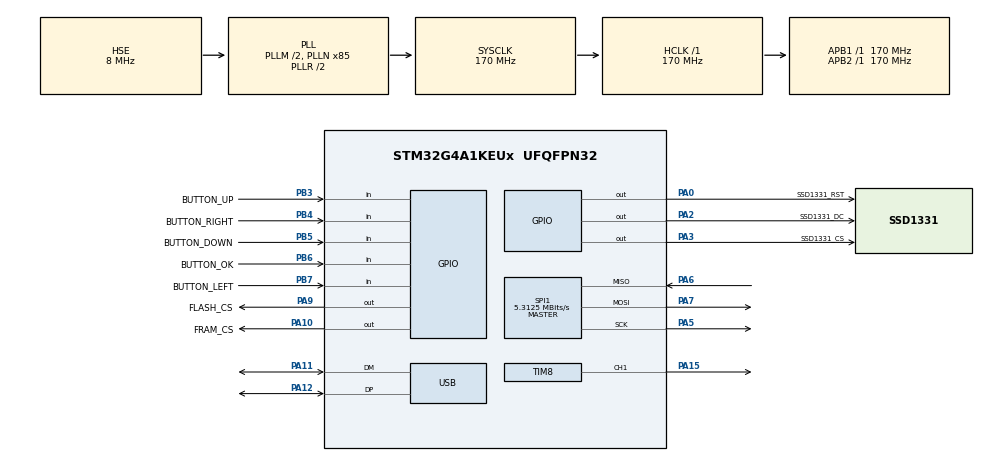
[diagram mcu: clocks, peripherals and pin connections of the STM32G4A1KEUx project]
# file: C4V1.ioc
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Dma.CORDIC_READ.0.Direction=DMA_PERIPH_TO_MEMORY
Dma.CORDIC_READ.0.EventEnable=DISABLE
Dma.CORDIC_READ.0.Instance=DMA1_Channel2
Dma.CORDIC_READ.0.MemDataAlignment=DMA_MDATAALIGN_WORD
Dma.CORDIC_READ.0.MemInc=DMA_MINC_ENABLE
Dma.CORDIC_READ.0.Mode=DMA_NORMAL
Dma.CORDIC_READ.0.PeriphDataAlignment=DMA_PDATAALIGN_WORD
Dma.CORDIC_READ.0.PeriphInc=DMA_PINC_DISABLE
Dma.CORDIC_READ.0.Polarity=HAL_DMAMUX_REQ_GEN_RISING
Dma.CORDIC_READ.0.Priority=DMA_PRIORITY_LOW
Dma.CORDIC_READ.0.RequestNumber=1
Dma.CORDIC_READ.0.SignalID=NONE
Dma.CORDIC_READ.0.SyncEnable=DISABLE
Dma.CORDIC_READ.0.SyncPolarity=HAL_DMAMUX_SYNC_NO_EVENT
Dma.CORDIC_READ.0.SyncRequestNumber=1
Dma.CORDIC_READ.0.SyncSignalID=NONE
Dma.CORDIC_WRITE.1.Direction=DMA_MEMORY_TO_PERIPH
Dma.CORDIC_WRITE.1.EventEnable=DISABLE
Dma.CORDIC_WRITE.1.Instance=DMA1_Channel3
Dma.CORDIC_WRITE.1.MemDataAlignment=DMA_MDATAALIGN_WORD
Dma.CORDIC_WRITE.1.MemInc=DMA_MINC_ENABLE
Dma.CORDIC_WRITE.1.Mode=DMA_NORMAL
Dma.CORDIC_WRITE.1.PeriphDataAlignment=DMA_PDATAALIGN_WORD
Dma.CORDIC_WRITE.1.PeriphInc=DMA_PINC_DISABLE
Dma.CORDIC_WRITE.1.Polarity=HAL_DMAMUX_REQ_GEN_RISING
Dma.CORDIC_WRITE.1.Priority=DMA_PRIORITY_LOW
Dma.CORDIC_WRITE.1.RequestNumber=1
Dma.CORDIC_WRITE.1.SignalID=NONE
Dma.CORDIC_WRITE.1.SyncEnable=DISABLE
Dma.CORDIC_WRITE.1.SyncPolarity=HAL_DMAMUX_SYNC_NO_EVENT
Dma.CORDIC_WRITE.1.SyncRequestNumber=1
Dma.CORDIC_WRITE.1.SyncSignalID=NONE
Dma.Request0=CORDIC_READ
Dma.Request1=CORDIC_WRITE
Dma.Request2=TIM8_CH1
Dma.TIM8_CH1.2.Direction=DMA_MEMORY_TO_PERIPH
Dma.TIM8_CH1.2.EventEnable=DISABLE
Dma.TIM8_CH1.2.Instance=DMA1_Channel1
Dma.TIM8_CH1.2.MemDataAlignment=DMA_MDATAALIGN_HALFWORD
Dma.TIM8_CH1.2.MemInc=DMA_MINC_ENABLE
Dma.TIM8_CH1.2.Mode=DMA_NORMAL
Dma.TIM8_CH1.2.PeriphDataAlignment=DMA_PDATAALIGN_HALFWORD
Dma.TIM8_CH1.2.PeriphInc=DMA_PINC_DISABLE
Dma.TIM8_CH1.2.Polarity=HAL_DMAMUX_REQ_GEN_RISING
Dma.TIM8_CH1.2.Priority=DMA_PRIORITY_VERY_HIGH
Dma.TIM8_CH1.2.RequestNumber=1
Dma.TIM8_CH1.2.SignalID=NONE
Dma.TIM8_CH1.2.SyncEnable=DISABLE
Dma.TIM8_CH1.2.SyncPolarity=HAL_DMAMUX_SYNC_NO_EVENT
Dma.TIM8_CH1.2.SyncRequestNumber=1
Dma.TIM8_CH1.2.SyncSignalID=NONE
Mcu.Family=STM32G4
Mcu.Name=STM32G4A1KEUx
Mcu.Package=UFQFPN32
NVIC.CORDIC_IRQn=true\:0\:0\:false\:true\:true\:3\:true\:true\:true
NVIC.DMA1_Channel1_IRQn=true\:0\:0\:false\:true\:true\:9\:false\:true\:true
NVIC.DMA1_Channel2_IRQn=true\:0\:0\:false\:true\:true\:1\:false\:true\:true
NVIC.DMA1_Channel3_IRQn=true\:0\:0\:false\:true\:true\:2\:false\:true\:true
NVIC.PriorityGroup=NVIC_PRIORITYGROUP_4
NVIC.TIM8_BRK_IRQn=true\:0\:0\:false\:true\:true\:5\:true\:true\:true
NVIC.TIM8_CC_IRQn=true\:0\:0\:false\:true\:true\:8\:true\:true\:true
NVIC.TIM8_TRG_COM_IRQn=true\:0\:0\:false\:true\:true\:7\:true\:true\:true
NVIC.TIM8_UP_IRQn=true\:0\:0\:false\:true\:true\:6\:true\:true\:true
NVIC.USB_LP_IRQn=true\:0\:0\:false\:true\:true\:4\:false\:true\:true
PA0.GPIO_Label=SSD1331_RST
PA0.GPIO_Speed=GPIO_SPEED_FREQ_VERY_HIGH
PA0.PinState=GPIO_PIN_SET
PA0.Signal=GPIO_Output
PA10.GPIO_Label=FRAM_CS
PA10.GPIO_Speed=GPIO_SPEED_FREQ_VERY_HIGH
PA10.PinState=GPIO_PIN_SET
PA10.Signal=GPIO_Output
PA11.Mode=Device
PA11.Signal=USB_DM
PA12.Mode=Device
PA12.Signal=USB_DP
PA13.Mode=Serial_Wire
PA13.Signal=SYS_JTMS-SWDIO
PA14.Mode=Serial_Wire
PA14.Signal=SYS_JTCK-SWCLK
PA15.GPIO_Speed=GPIO_SPEED_FREQ_VERY_HIGH
PA15.Signal=S_TIM8_CH1
PA2.GPIO_Label=SSD1331_DC
PA2.Signal=GPIO_Output
PA3.GPIO_Label=SSD1331_CS
PA3.GPIO_Speed=GPIO_SPEED_FREQ_VERY_HIGH
PA3.PinState=GPIO_PIN_SET
PA3.Signal=GPIO_Output
PA5.GPIO_Speed=GPIO_SPEED_FREQ_VERY_HIGH
PA5.Mode=Full_Duplex_Master
PA5.Signal=SPI1_SCK
PA6.GPIO_Speed=GPIO_SPEED_FREQ_VERY_HIGH
PA6.Mode=Full_Duplex_Master
PA6.Signal=SPI1_MISO
PA7.GPIO_Speed=GPIO_SPEED_FREQ_VERY_HIGH
PA7.Mode=Full_Duplex_Master
PA7.Signal=SPI1_MOSI
PA9.GPIO_Label=FLASH_CS
PA9.GPIO_ModeDefaultOutputPP=GPIO_MODE_OUTPUT_OD
PA9.GPIO_PuPd=GPIO_PULLUP
PA9.GPIO_Speed=GPIO_SPEED_FREQ_VERY_HIGH
PA9.PinState=GPIO_PIN_SET
PA9.Signal=GPIO_Output
PB3.GPIO_Label=BUTTON_UP
PB3.Signal=GPIO_Input
PB4.GPIO_Label=BUTTON_RIGHT
PB4.Signal=GPIO_Input
PB5.GPIO_Label=BUTTON_DOWN
PB5.Signal=GPIO_Input
PB6.GPIO_Label=BUTTON_OK
PB6.GPIO_PuPd=GPIO_PULLUP
PB6.Signal=GPIO_Input
PB7.GPIO_Label=BUTTON_LEFT
PB7.GPIO_PuPd=GPIO_PULLUP
PB7.Signal=GPIO_Input
PF0-OSC_IN.Mode=HSE-External-Oscillator
PF0-OSC_IN.Signal=RCC_OSC_IN
PF1-OSC_OUT.Mode=HSE-External-Oscillator
PF1-OSC_OUT.Signal=RCC_OSC_OUT
ProjectManager.HeapSize=0xf00
ProjectManager.StackSize=0x1f00
ProjectManager.TargetToolchain=STM32CubeIDE
RCC.ADC12Freq_Value=170000000
RCC.ADC345Freq_Value=170000000
RCC.AHBFreq_Value=170000000
RCC.APB1Freq_Value=170000000
RCC.APB1TimFreq_Value=170000000
RCC.APB2Freq_Value=170000000
RCC.APB2TimFreq_Value=170000000
RCC.CortexFreq_Value=170000000
RCC.EXTERNAL_CLOCK_VALUE=12288000
RCC.HCLKFreq_Value=170000000
RCC.HSE_VALUE=8000000
RCC.HSI48_VALUE=48000000
RCC.HSI_VALUE=16000000
RCC.LSE_VALUE=32768
RCC.PLLM=RCC_PLLM_DIV2
RCC.PLLN=85
RCC.PLLSourceVirtual=RCC_PLLSOURCE_HSE
RCC.SYSCLKFreq_VALUE=170000000
RCC.SYSCLKSource=RCC_SYSCLKSOURCE_PLLCLK
RCC.USBFreq_Value=48000000
RCC.VCOOutputFreq_Value=340000000
SH.S_TIM8_CH1.0=TIM8_CH1,PWM Generation1 CH1
SPI1.BaudRatePrescaler=SPI_BAUDRATEPRESCALER_32
SPI1.CalculateBaudRate=5.3125 MBits/s
SPI1.Direction=SPI_DIRECTION_2LINES
SPI1.Mode=SPI_MODE_MASTER
SPI1.VirtualType=VM_MASTER
TIM8.Channel-PWM\ Generation1\ CH1=TIM_CHANNEL_1
TIM8.OCIdleState_1=TIM_OCIDLESTATE_SET
TIM8.PeriodNoDither=212
USB.Sof_enable=DISABLE
USB.low_power_enable=DISABLE
USB_DEVICE.CLASS_NAME_FS=HID
USB_DEVICE.MANUFACTURER_STRING=CryptographyKey
USB_DEVICE.PRODUCT_STRING_HID_FS=CryptographyKey
USB_DEVICE.VirtualMode=Hid
USB_DEVICE.VirtualModeFS=Hid_FS
VP_CORDIC_VS_CORDIC.Mode=CORDIC_Activate
VP_RNG_VS_RNG.Mode=RNG_Activate
VP_TIM8_VS_ClockSourceINT.Mode=Internal
VP_USB_DEVICE_VS_USB_DEVICE_HID_FS.Mode=HID_FS
board=custom

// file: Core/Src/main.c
/* USER CODE BEGIN Header */
/**
 ******************************************************************************
 * @file           : main.c
 * @brief          : Main program body
 ******************************************************************************
 * @attention
 *
 * Copyright (c) 2023 STMicroelectronics.
 * All rights reserved.
 *
 * This software is licensed under terms that can be found in the LICENSE file
 * in the root directory of this software component.
 * If no LICENSE file comes with this software, it is provided AS-IS.
 *
 ******************************************************************************
 */
/* USER CODE END Header */
#include "main.h"
#include "cordic.h"
#include "dma.h"
#include "rng.h"
#include "spi.h"
#include "tim.h"
#include "usb_device.h"
#include "gpio.h"

/* USER CODE BEGIN Includes */
#include "SM.h"

/* USER CODE END Includes */

void SystemClock_Config(void);
static void MX_NVIC_Init(void);

int main(void)
{

  /* MCU Configuration--------------------------------------------------------*/

  /* Reset of all peripherals, Initializes the Flash interface and the Systick. */
  HAL_Init();

  /* Configure the system clock */
  SystemClock_Config();

  /* Initialize all configured peripherals */
  MX_GPIO_Init();
  MX_DMA_Init();
  MX_RNG_Init();
  MX_USB_Device_Init();
  MX_CORDIC_Init();
  MX_TIM8_Init();
  MX_SPI1_Init();

  /* Initialize interrupts */
  MX_NVIC_Init();

  /* Infinite loop */
  /* USER CODE BEGIN WHILE */
   while(1)
   {
      SM_Handle();
    /* USER CODE END WHILE */

   }
}

void SystemClock_Config(void)
{
  RCC_OscInitTypeDef RCC_OscInitStruct = {0};
  RCC_ClkInitTypeDef RCC_ClkInitStruct = {0};

  /** Configure the main internal regulator output voltage
  */
  HAL_PWREx_ControlVoltageScaling(PWR_REGULATOR_VOLTAGE_SCALE1_BOOST);

  /** Initializes the RCC Oscillators according to the specified parameters
  * in the RCC_OscInitTypeDef structure.
  */
  RCC_OscInitStruct.OscillatorType = RCC_OSCILLATORTYPE_HSI48|RCC_OSCILLATORTYPE_HSE;
  RCC_OscInitStruct.HSEState = RCC_HSE_ON;
  RCC_OscInitStruct.HSI48State = RCC_HSI48_ON;
  RCC_OscInitStruct.PLL.PLLState = RCC_PLL_ON;
  RCC_OscInitStruct.PLL.PLLSource = RCC_PLLSOURCE_HSE;
  RCC_OscInitStruct.PLL.PLLM = RCC_PLLM_DIV2;
  RCC_OscInitStruct.PLL.PLLN = 85;
  RCC_OscInitStruct.PLL.PLLP = RCC_PLLP_DIV2;
  RCC_OscInitStruct.PLL.PLLQ = RCC_PLLQ_DIV2;
  RCC_OscInitStruct.PLL.PLLR = RCC_PLLR_DIV2;
  if (HAL_RCC_OscConfig(&RCC_OscInitStruct) != HAL_OK)
  {
    Error_Handler();
  }

  /** Initializes the CPU, AHB and APB buses clocks
  */
  RCC_ClkInitStruct.ClockType = RCC_CLOCKTYPE_HCLK|RCC_CLOCKTYPE_SYSCLK
                              |RCC_CLOCKTYPE_PCLK1|RCC_CLOCKTYPE_PCLK2;
  RCC_ClkInitStruct.SYSCLKSource = RCC_SYSCLKSOURCE_PLLCLK;
  RCC_ClkInitStruct.AHBCLKDivider = RCC_SYSCLK_DIV1;
  RCC_ClkInitStruct.APB1CLKDivider = RCC_HCLK_DIV1;
  RCC_ClkInitStruct.APB2CLKDivider = RCC_HCLK_DIV1;

  if (HAL_RCC_ClockConfig(&RCC_ClkInitStruct, FLASH_LATENCY_4) != HAL_OK)
  {
    Error_Handler();
  }
}

/**
  * @brief NVIC Configuration.
  * @retval None
  */
static void MX_NVIC_Init(void)
{
  /* DMA1_Channel2_IRQn interrupt configuration */
  HAL_NVIC_SetPriority(DMA1_Channel2_IRQn, 0, 0);
  HAL_NVIC_EnableIRQ(DMA1_Channel2_IRQn);
  /* DMA1_Channel3_IRQn interrupt configuration */
  HAL_NVIC_SetPriority(DMA1_Channel3_IRQn, 0, 0);
  HAL_NVIC_EnableIRQ(DMA1_Channel3_IRQn);
  /* CORDIC_IRQn interrupt configuration */
  HAL_NVIC_SetPriority(CORDIC_IRQn, 0, 0);
  HAL_NVIC_EnableIRQ(CORDIC_IRQn);
  /* USB_LP_IRQn interrupt configuration */
  HAL_NVIC_SetPriority(USB_LP_IRQn, 0, 0);
  HAL_NVIC_EnableIRQ(USB_LP_IRQn);
  /* TIM8_BRK_IRQn interrupt configuration */
  HAL_NVIC_SetPriority(TIM8_BRK_IRQn, 0, 0);
  HAL_NVIC_EnableIRQ(TIM8_BRK_IRQn);
  /* TIM8_UP_IRQn interrupt configuration */
  HAL_NVIC_SetPriority(TIM8_UP_IRQn, 0, 0);
  HAL_NVIC_EnableIRQ(TIM8_UP_IRQn);
  /* TIM8_TRG_COM_IRQn interrupt configuration */
  HAL_NVIC_SetPriority(TIM8_TRG_COM_IRQn, 0, 0);
  HAL_NVIC_EnableIRQ(TIM8_TRG_COM_IRQn);
  /* TIM8_CC_IRQn interrupt configuration */
  HAL_NVIC_SetPriority(TIM8_CC_IRQn, 0, 0);
  HAL_NVIC_EnableIRQ(TIM8_CC_IRQn);
  /* DMA1_Channel1_IRQn interrupt configuration */
  HAL_NVIC_SetPriority(DMA1_Channel1_IRQn, 0, 0);
  HAL_NVIC_EnableIRQ(DMA1_Channel1_IRQn);
}

void Error_Handler(void)
{
   __disable_irq();
   while(1)
   {
   }
}

#ifdef  USE_FULL_ASSERT
/**
  * @brief  Reports the name of the source file and the source line number
  *         where the assert_param error has occurred.
  * @param  file: pointer to the source file name
  * @param  line: assert_param error line source number
  * @retval None
  */
void assert_failed(uint8_t *file, uint32_t line)
{
  /* USER CODE BEGIN 6 */
   /* User can add his own implementation to report the file name and line
      number, ex: printf("Wrong parameters value: file %s on line %d\r\n", file,
      line) */
  /* USER CODE END 6 */
}
#endif /* USE_FULL_ASSERT */
